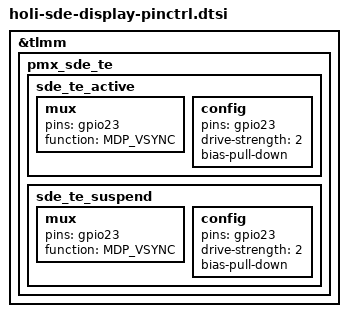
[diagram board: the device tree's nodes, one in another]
&tlmm {
	pmx_sde_te: pmx_sde_te {
		sde_te_active: sde_te_active {
			mux {
				pins = "gpio23";
				function = "MDP_VSYNC";
			};

			config {
				pins = "gpio23";
				drive-strength = <2>;   /* 2 mA */
				bias-pull-down;         /* PULL DOWN */
			};
		};

		sde_te_suspend: sde_te_suspend {
			mux {
				pins = "gpio23";
				function = "MDP_VSYNC";
			};

			config {
				pins = "gpio23";
				drive-strength = <2>;   /* 2 mA */
				bias-pull-down;         /* PULL DOWN */
			};
		};
	};
};
